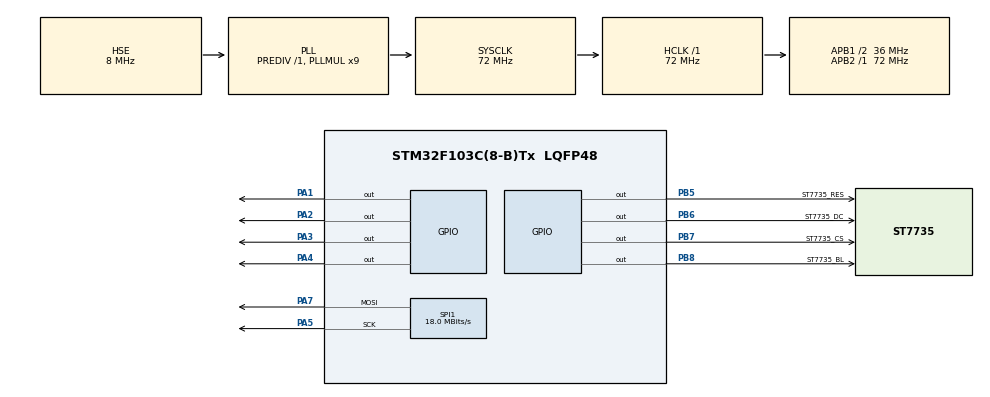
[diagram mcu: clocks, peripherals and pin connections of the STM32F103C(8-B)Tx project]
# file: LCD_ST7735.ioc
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Dma.Request0=SPI1_TX
Dma.SPI1_TX.0.Direction=DMA_MEMORY_TO_PERIPH
Dma.SPI1_TX.0.Instance=DMA1_Channel3
Dma.SPI1_TX.0.MemDataAlignment=DMA_MDATAALIGN_BYTE
Dma.SPI1_TX.0.MemInc=DMA_MINC_ENABLE
Dma.SPI1_TX.0.Mode=DMA_NORMAL
Dma.SPI1_TX.0.PeriphDataAlignment=DMA_PDATAALIGN_BYTE
Dma.SPI1_TX.0.PeriphInc=DMA_PINC_DISABLE
Dma.SPI1_TX.0.Priority=DMA_PRIORITY_MEDIUM
Mcu.Family=STM32F1
Mcu.Name=STM32F103C(8-B)Tx
Mcu.Package=LQFP48
NVIC.DMA1_Channel3_IRQn=true\:0\:0\:false\:false\:true\:false\:true\:true
NVIC.PriorityGroup=NVIC_PRIORITYGROUP_4
PA1.GPIO_Speed=GPIO_SPEED_FREQ_HIGH
PA1.Signal=GPIO_Output
PA13.Mode=Serial_Wire
PA13.Signal=SYS_JTMS-SWDIO
PA14.Mode=Serial_Wire
PA14.Signal=SYS_JTCK-SWCLK
PA2.GPIO_Speed=GPIO_SPEED_FREQ_HIGH
PA2.Signal=GPIO_Output
PA3.GPIO_Speed=GPIO_SPEED_FREQ_HIGH
PA3.Signal=GPIO_Output
PA4.GPIO_Speed=GPIO_SPEED_FREQ_HIGH
PA4.Signal=GPIO_Output
PA5.Mode=TX_Only_Simplex_Unidirect_Master
PA5.Signal=SPI1_SCK
PA7.Mode=TX_Only_Simplex_Unidirect_Master
PA7.Signal=SPI1_MOSI
PB5.GPIO_Label=ST7735_RES
PB5.GPIO_Speed=GPIO_SPEED_FREQ_HIGH
PB5.Signal=GPIO_Output
PB6.GPIO_Label=ST7735_DC
PB6.GPIO_Speed=GPIO_SPEED_FREQ_HIGH
PB6.Signal=GPIO_Output
PB7.GPIO_Label=ST7735_CS
PB7.GPIO_Speed=GPIO_SPEED_FREQ_HIGH
PB7.Signal=GPIO_Output
PB8.GPIO_Label=ST7735_BL
PB8.GPIO_Speed=GPIO_SPEED_FREQ_HIGH
PB8.Signal=GPIO_Output
PD0-OSC_IN.Mode=HSE-External-Oscillator
PD0-OSC_IN.Signal=RCC_OSC_IN
PD1-OSC_OUT.Mode=HSE-External-Oscillator
PD1-OSC_OUT.Signal=RCC_OSC_OUT
ProjectManager.HeapSize=0x200
ProjectManager.StackSize=0x400
ProjectManager.TargetToolchain=MDK-ARM V5.32
RCC.AHBFreq_Value=72000000
RCC.APB1CLKDivider=RCC_HCLK_DIV2
RCC.APB1Freq_Value=36000000
RCC.APB1TimFreq_Value=72000000
RCC.APB2Freq_Value=72000000
RCC.APB2TimFreq_Value=72000000
RCC.HCLKFreq_Value=72000000
RCC.PLLMUL=RCC_PLL_MUL9
RCC.PLLSourceVirtual=RCC_PLLSOURCE_HSE
RCC.SYSCLKFreq_VALUE=72000000
RCC.SYSCLKSource=RCC_SYSCLKSOURCE_PLLCLK
RCC.USBFreq_Value=72000000
SPI1.BaudRatePrescaler=SPI_BAUDRATEPRESCALER_4
SPI1.CLKPhase=SPI_PHASE_2EDGE
SPI1.CLKPolarity=SPI_POLARITY_HIGH
SPI1.CalculateBaudRate=18.0 MBits/s
SPI1.Direction=SPI_DIRECTION_2LINES
SPI1.Mode=SPI_MODE_MASTER
SPI1.VirtualType=VM_MASTER
board=custom

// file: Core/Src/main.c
/* USER CODE BEGIN Header */
/**
  ******************************************************************************
  * @file           : main.c
  * @brief          : Main program body
  ******************************************************************************
  * @attention
  *
  * Copyright (c) 2026 STMicroelectronics.
  * All rights reserved.
  *
  * This software is licensed under terms that can be found in the LICENSE file
  * in the root directory of this software component.
  * If no LICENSE file comes with this software, it is provided AS-IS.
  *
  ******************************************************************************
  */
/* USER CODE END Header */
#include "main.h"
#include "dma.h"
#include "spi.h"
#include "gpio.h"

/* USER CODE BEGIN Includes */
#include "st7735.h"
#include "lcd_test.h"
#include "pic.h"
/* USER CODE END Includes */

void SystemClock_Config(void);

int main(void)
{

  /* MCU Configuration--------------------------------------------------------*/

  /* Reset of all peripherals, Initializes the Flash interface and the Systick. */
  HAL_Init();

  /* Configure the system clock */
  SystemClock_Config();

  /* Initialize all configured peripherals */
  MX_GPIO_Init();
  MX_DMA_Init();
  MX_SPI1_Init();
  /* USER CODE BEGIN 2 */
  LCD_Init();
  LCD_Fill(0,0,LCD_W,LCD_H,WHITE);
  //==============================================================//
  //LCD_DrawLine_Test();
  //LCD_DrawRectangle_Test();
  //Draw_Circle_Test();
//  float t=0;
  /* USER CODE END 2 */

  /* Infinite loop */
  while (1)
  {

    /* USER CODE BEGIN 3 */
//    LCD_ShowChinese(0,0,"���ӿƼ�",BLUE,WHITE,24,0);
//    LCD_ShowString(24,30,"LCD_W:",RED,WHITE,16,0);
//    LCD_ShowIntNum(72,30,LCD_W,3,RED,WHITE,16);
//    LCD_ShowString(24,50,"LCD_H:",RED,WHITE,16,0);
//    LCD_ShowIntNum(72,50,LCD_H,3,RED,WHITE,16);
//    LCD_ShowFloatNum1(20,80,t,4,RED,WHITE,16);
//    t+=0.11;
//    LCD_ShowPicture(65,80,40,40,gImage_kaiyan);
//      LCD_ShowPicture(0,30,64,17,gImage_64_17_kaiyan);
      LCD_ShowPicture(39,55,50,50,gImage_esrth50x50);
  }
  /* USER CODE END 3 */
}

void SystemClock_Config(void)
{
  RCC_OscInitTypeDef RCC_OscInitStruct = {0};
  RCC_ClkInitTypeDef RCC_ClkInitStruct = {0};

  /** Initializes the RCC Oscillators according to the specified parameters
  * in the RCC_OscInitTypeDef structure.
  */
  RCC_OscInitStruct.OscillatorType = RCC_OSCILLATORTYPE_HSE;
  RCC_OscInitStruct.HSEState = RCC_HSE_ON;
  RCC_OscInitStruct.HSEPredivValue = RCC_HSE_PREDIV_DIV1;
  RCC_OscInitStruct.HSIState = RCC_HSI_ON;
  RCC_OscInitStruct.PLL.PLLState = RCC_PLL_ON;
  RCC_OscInitStruct.PLL.PLLSource = RCC_PLLSOURCE_HSE;
  RCC_OscInitStruct.PLL.PLLMUL = RCC_PLL_MUL9;
  if (HAL_RCC_OscConfig(&RCC_OscInitStruct) != HAL_OK)
  {
    Error_Handler();
  }

  /** Initializes the CPU, AHB and APB buses clocks
  */
  RCC_ClkInitStruct.ClockType = RCC_CLOCKTYPE_HCLK|RCC_CLOCKTYPE_SYSCLK
                              |RCC_CLOCKTYPE_PCLK1|RCC_CLOCKTYPE_PCLK2;
  RCC_ClkInitStruct.SYSCLKSource = RCC_SYSCLKSOURCE_PLLCLK;
  RCC_ClkInitStruct.AHBCLKDivider = RCC_SYSCLK_DIV1;
  RCC_ClkInitStruct.APB1CLKDivider = RCC_HCLK_DIV2;
  RCC_ClkInitStruct.APB2CLKDivider = RCC_HCLK_DIV1;

  if (HAL_RCC_ClockConfig(&RCC_ClkInitStruct, FLASH_LATENCY_2) != HAL_OK)
  {
    Error_Handler();
  }
}

void Error_Handler(void)
{
  __disable_irq();
  while (1)
  {
  }
}
